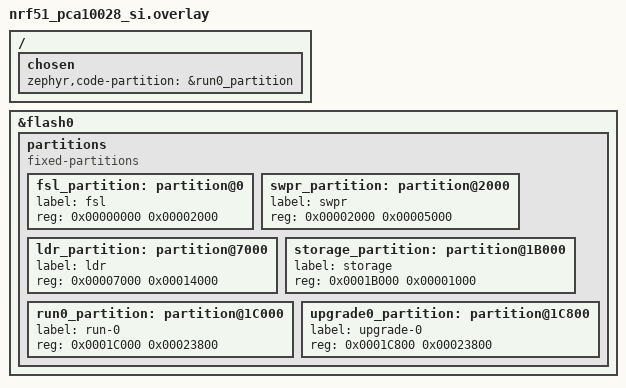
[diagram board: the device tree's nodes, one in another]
/*
 * Copyright (c) 2019 Laczen
 *
 * Overlay file for ZB-8 single image setup
 *
 * SPDX-License-Identifier: Apache-2.0
 */

/delete-node/ &boot_partition;
/delete-node/ &scratch_partition;
/delete-node/ &slot0_partition;
/delete-node/ &slot1_partition;
/delete-node/ &storage_partition;

/ {
	chosen {
		zephyr,code-partition = &run0_partition;
	};
};

&flash0 {
	/*
	 * For more information, see:
	 * http://docs.zephyrproject.org/latest/guides/dts/index.html#flash-partitions
	 */
	partitions {
		compatible = "fixed-partitions";
		#address-cells = <1>;
		#size-cells = <1>;

		fsl_partition: partition@0 {
			label = "fsl";
			reg = <0x00000000 0x00002000>;
		};
		swpr_partition: partition@2000 {
			label = "swpr";
			reg = <0x00002000 0x00005000>;
		};
		ldr_partition: partition@7000 {
			label = "ldr";
			reg = <0x00007000 0x00014000>;
		};
		storage_partition: partition@1B000 {
			label = "storage";
			reg = <0x0001B000 0x00001000>;
		};
		run0_partition: partition@1C000 {
			label = "run-0";
			reg = <0x0001C000 0x00023800>;
		};
		upgrade0_partition: partition@1C800 {
			label = "upgrade-0";
			reg = <0x0001C800 0x00023800>;
		};
	};
};
